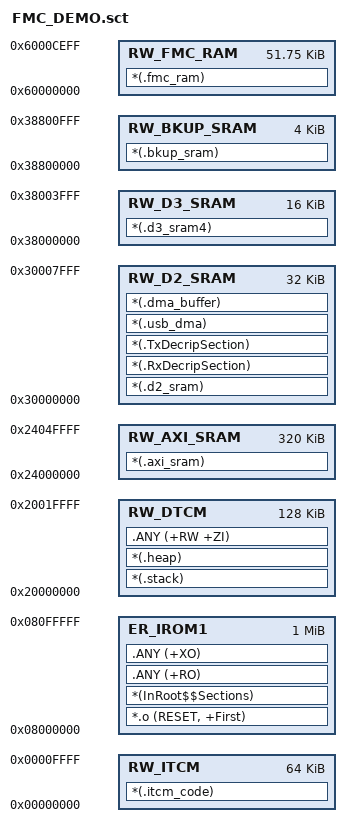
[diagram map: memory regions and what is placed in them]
; *************************************************************
; *** STM32H723ZGT6 最终版分散加载描述文件 (包含 FMC 扩展)        ***
; *** 适用平台：STM32H723ZGT6 (Cortex-M7, 1MB Flash, 564KB RAM) ***
; *** 数据基准：DS13313 Datasheet & RM0468 Reference Manual    ***
; *************************************************************

LR_IROM1 0x08000000 0x00100000  {    ; 加载域: 内部 Flash，起始 0x08000000，大小 1MB

  ; ------------------------------------------------------------
  ; 1. 默认执行域：内部 Flash (主代码区)
  ; ------------------------------------------------------------
  ER_IROM1 0x08000000 0x00100000  {
   *.o (RESET, +First)
   *(InRoot$$Sections)
   .ANY (+RO)
   .ANY (+XO)
  }

  ; ------------------------------------------------------------
  ; 2. 独立执行域：ITCM (零等待强实时指令池)
  ; ------------------------------------------------------------
  RW_ITCM 0x00000000 0x00010000 {    ; 物理容量: 64KB
   *(.itcm_code)
  }

  ; ------------------------------------------------------------
  ; 3. 独立执行域：DTCM (内核高速数据区，禁止通用 DMA 访问)
  ; ------------------------------------------------------------
  RW_DTCM 0x20000000 0x00020000  {   ; 物理容量: 128KB
   *(.stack)
   *(.heap)
   .ANY (+RW +ZI)
  }

  ; ------------------------------------------------------------
  ; 4. 独立执行域：AXI SRAM (D1 域大体积缓存/MDMA专属)
  ; ------------------------------------------------------------
  RW_AXI_SRAM 0x24000000 0x00050000  { ; 物理容量: 320KB
   *(.axi_sram)
  }

  ; ------------------------------------------------------------
  ; 5. 独立执行域：D2 SRAM (网络与常规外设 DMA 专用数据池)
  ;    包含物理连续的 SRAM1 (16KB) 与 SRAM2 (16KB)
  ; ------------------------------------------------------------
  RW_D2_SRAM 0x30000000 0x00008000 {   ; 物理容量: 32KB
   *(.d2_sram)
   *(.RxDecripSection)
   *(.TxDecripSection)
   *(.usb_dma)
   *(.dma_buffer)
  }

  ; ------------------------------------------------------------
  ; 6. 独立执行域：D3 SRAM (低功耗模式驻留与 BDMA 专用)
  ; ------------------------------------------------------------
  RW_D3_SRAM 0x38000000 0x00004000 {   ; 物理容量: 16KB
   *(.d3_sram4)
  }

  ; ------------------------------------------------------------
  ; 7. 独立执行域：备份 SRAM (由 VBAT 供电)
  ; ------------------------------------------------------------
  RW_BKUP_SRAM 0x38800000 0x00001000  { ; 物理容量: 4KB
   *(.bkup_sram)
  }

  ; ------------------------------------------------------------
  ; 8. 独立执行域：FMC 外部存储 (Bank 1)
  ; ------------------------------------------------------------
  RW_FMC_RAM 0x60000000 0x0000CF00  {
   *(.fmc_ram)                       ; C 语言中使用 __attribute__((section(".fmc_ram"))) 分配外部变量
  }
}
